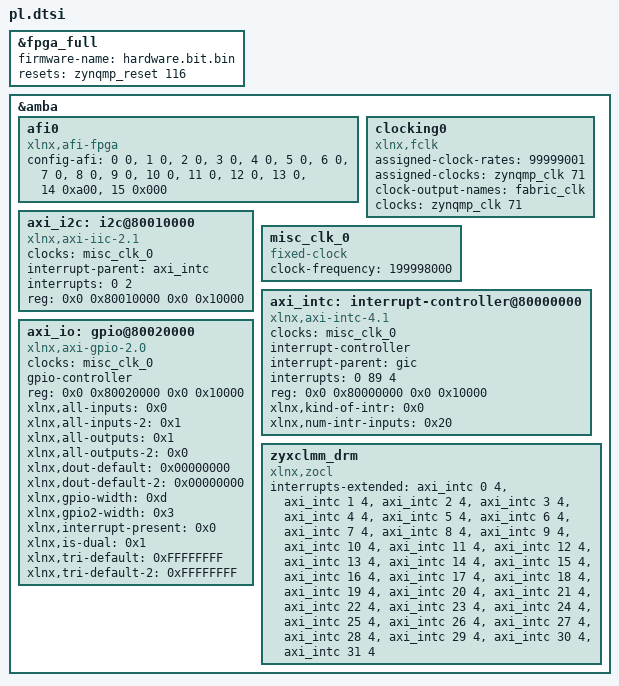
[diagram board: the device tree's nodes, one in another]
/*
 * CAUTION: This file is automatically generated by Xilinx.
 * Version:  
 * Today is: Tue Jan 18 05:12:38 2022
 */


/dts-v1/;
/plugin/;
/ {
	fragment@0 {
		target = <&fpga_full>;
		overlay0: __overlay__ {
			#address-cells = <2>;
			#size-cells = <2>;
			firmware-name = "hardware.bit.bin";
			resets = <&zynqmp_reset 116>;
		};
	};
	fragment@1 {
		target = <&amba>;
		overlay1: __overlay__ {
			afi0: afi0 {
				compatible = "xlnx,afi-fpga";
				config-afi = < 0 0>, <1 0>, <2 0>, <3 0>, <4 0>, <5 0>, <6 0>, <7 0>, <8 0>, <9 0>, <10 0>, <11 0>, <12 0>, <13 0>, <14 0xa00>, <15 0x000>;
			};
			clocking0: clocking0 {
				#clock-cells = <0>;
				assigned-clock-rates = <99999001>;
				assigned-clocks = <&zynqmp_clk 71>;
				clock-output-names = "fabric_clk";
				clocks = <&zynqmp_clk 71>;
				compatible = "xlnx,fclk";
			};
		};
	};
	fragment@2 {
		target = <&amba>;
		overlay2: __overlay__ {
			#address-cells = <2>;
			#size-cells = <2>;
			axi_i2c: i2c@80010000 {
				#address-cells = <1>;
				#size-cells = <0>;
				clock-names = "s_axi_aclk";
				clocks = <&misc_clk_0>;
				compatible = "xlnx,axi-iic-2.1", "xlnx,xps-iic-2.00.a";
				interrupt-names = "iic2intc_irpt";
				interrupt-parent = <&axi_intc>;
				interrupts = <0 2>;
				reg = <0x0 0x80010000 0x0 0x10000>;
			};
			misc_clk_0: misc_clk_0 {
				#clock-cells = <0>;
				clock-frequency = <199998000>;
				compatible = "fixed-clock";
			};
			axi_intc: interrupt-controller@80000000 {
				#interrupt-cells = <2>;
				clock-names = "s_axi_aclk";
				clocks = <&misc_clk_0>;
				compatible = "xlnx,axi-intc-4.1", "xlnx,xps-intc-1.00.a";
				interrupt-controller ;
				interrupt-names = "irq";
				interrupt-parent = <&gic>;
				interrupts = <0 89 4>;
				reg = <0x0 0x80000000 0x0 0x10000>;
				xlnx,kind-of-intr = <0x0>;
				xlnx,num-intr-inputs = <0x20>;
			};
			axi_io: gpio@80020000 {
				#gpio-cells = <3>;
				clock-names = "s_axi_aclk";
				clocks = <&misc_clk_0>;
				compatible = "xlnx,axi-gpio-2.0", "xlnx,xps-gpio-1.00.a";
				gpio-controller ;
				reg = <0x0 0x80020000 0x0 0x10000>;
				xlnx,all-inputs = <0x0>;
				xlnx,all-inputs-2 = <0x1>;
				xlnx,all-outputs = <0x1>;
				xlnx,all-outputs-2 = <0x0>;
				xlnx,dout-default = <0x00000000>;
				xlnx,dout-default-2 = <0x00000000>;
				xlnx,gpio-width = <0xd>;
				xlnx,gpio2-width = <0x3>;
				xlnx,interrupt-present = <0x0>;
				xlnx,is-dual = <0x1>;
				xlnx,tri-default = <0xFFFFFFFF>;
				xlnx,tri-default-2 = <0xFFFFFFFF>;
			};
			zyxclmm_drm {
				compatible = "xlnx,zocl";
				interrupts-extended = <&axi_intc 0 4>, <&axi_intc 1 4>, <&axi_intc 2 4>, <&axi_intc 3 4>, <&axi_intc 4 4>, <&axi_intc 5 4>, <&axi_intc 6 4>, <&axi_intc 7 4>, <&axi_intc 8 4>, <&axi_intc 9 4>,
<&axi_intc 10 4>, <&axi_intc 11 4>, <&axi_intc 12 4>, <&axi_intc 13 4>, <&axi_intc 14 4>,
<&axi_intc 15 4>, <&axi_intc 16 4>, <&axi_intc 17 4>, <&axi_intc 18 4>, <&axi_intc 19 4>,
<&axi_intc 20 4>, <&axi_intc 21 4>, <&axi_intc 22 4>, <&axi_intc 23 4>, <&axi_intc 24 4>,
<&axi_intc 25 4>, <&axi_intc 26 4>, <&axi_intc 27 4>, <&axi_intc 28 4>, <&axi_intc 29 4>,
<&axi_intc 30 4>, <&axi_intc 31 4 >;
			};
		};
	};
};
